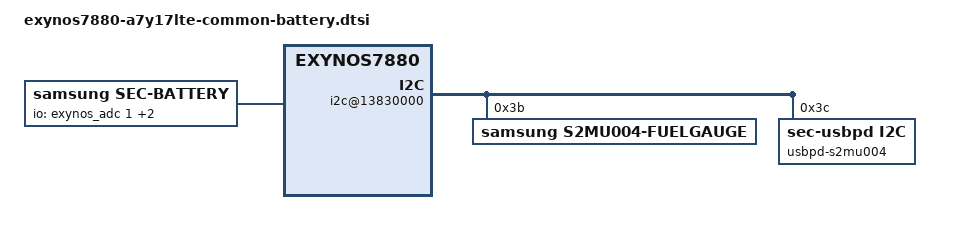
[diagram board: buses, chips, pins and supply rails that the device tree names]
/*
 * SAMSUNG UNIVERSAL7880 board device tree source
 *
 * Copyright (c) 2016 Samsung Electronics Co., Ltd.
 *		http://www.samsung.com
 *
 * This program is free software; you can redistribute it and/or modify
 * it under the terms of the GNU General Public License version 2 as
 * published by the Free Software Foundation.
*/

/ {
	pinctrl@139F0000 {
		fuel_irq: fuel-irq {
			samsung,pins = "gpa0-3";
			samsung,pin-function = <0>;
			samsung,pin-pud = <2>;
			samsung,pin-drv = <0>;
		};

		if_pmic_irq: if-pmic-irq {
			samsung,pins = "gpa2-7";
			samsung,pin-function = <0>;
			samsung,pin-pud = <0>;
			samsung,pin-drv = <0>;
		};

		usbpd_irq: usbpd-irq {
			samsung,pins = "gpa1-3";
			samsung,pin-function = <0xf>;
			samsung,pin-pud = <0>;
			samsung,pin-drv = <0>;
		};
	};

	i2c@13830000 {
		i2c-gpio,delay-us = <5>;
		status = "okay";
		s2mu004-fuelgauge@3B {
			compatible = "samsung,s2mu004-fuelgauge";
			reg = <0x3B>;
			pinctrl-names = "default";
			pinctrl-0 = <&fuel_irq>;
			fuelgauge,fuel_int = <&gpa0 3 0>;
			fuelgauge,fuel_alert_soc = <1>;
			fuelgauge,fuel_alert_vol = <3300>;
			fuelgauge,capacity_max = <1000>;
			fuelgauge,capacity_max_margin = <200>;
			fuelgauge,capacity_min = <0>;
			fuelgauge,capacity_calculation_type = <28>;
			fuelgauge,capacity_full = <3600>;
			fuelgauge,type_str = "SDI";
			fuelgauge,model_type = <1>;
		};
		usbpd-s2mu004@3C {
			compatible = "sec-usbpd,i2c";
			reg = <0x3C>;
			pinctrl-names = "default";
			pinctrl-0     = <&usbpd_irq>;
			usbpd,usbpd_int = <&gpa1 3 0>;
		};
	};

	battery_params {
			battery,battery_data = 
				<
				/***** battery data for 4.35 *****/
				/* battery,battery_table3 */
				229 11 83 11 193 10 48 10 182 9
				67 9 215 8 111 8 244 7 174 7
				84 7 244 6 182 6 136 6 100 6
				70 6 34 6 249 5 199 5 145 5
				57 5 175 1 243 8 132 8 21 8
				166 7 55 7 200 6 89 6 235 5
				124 5 13 5 158 4 47 4 192 3
				81 3 227 2 116 2 5 2 150 1
				39 1 184 0 73 0 219 15

				/* battery,battery_table4 */
				51 51 51 51 51 51 50 51 50 50
				50 51 51 52 53 53 54 56 58 63
				80 154

				/* battery,batcap */
				0x40 0x38 0x10 0x0E /* [0x0E] [0x0F] [0x10] [0x11] */
				/* battery,accum */ 
				0x7 0xD7 /* [0x45] [0x44] */

				/* battery,soc_arr_val */
				11185 10644 10103 9561 9020 8479 7937 7396 6855 6314 5772 5231 4690 4148 3607 3066 2525 1983 1442 901 359 (-182)
				/* battery,ocv_arr_val */
				44709 44058 43407 42757 42157 41576 41022 40501 40016 39595 39118 38638 38351 38136 37965 37820 37654 37444 37170 36926 36174 31965


				/***** battery data for 4.33 *****/
				/* battery,battery_table3 */
				101 11 233 10 110 10 242 9 123 9
				10 9 158 8 56 8 222 7 135 7
				26 7 209 6 158 6 119 6 87 6
				59 6 26 6 239 5 182 5 132 5
				63 5 211 1 222 8 111 8 0 8
				145 7 34 7 179 6 68 6 213 5
				101 5 246 4 135 4 24 4 169 3
				58 3 203 2 92 2 237 1 125 1
				14 1 159 0 48 0 202 15

				/* battery,battery_table4 */
				58 58 58 57 55 55 54 53 53 53
				52 52 53 53 54 54 55 54 58 59
				72 163

				/* battery,batcap */
				0x30 0x34 0x0C 0x0D /* [0x0E] [0x0F] [0x10] [0x11] */
				/* battery,accum */
				0x8 0x00 /* [0x45] [0x44] */

				/* battery,soc_arr_val */
				11084 10542 10000 9458 8915 8373 7830 7288 6745 6202 5660 5117 4575 4032 3490 2947 2405 1862 1320 778 235 (-265)
				/* battery,ocv_arr_val */
				44241 43638 43035 42432 41851 41297 40771 40276 39834 39407 38875 38520 38274 38081 37927 37790 37626 37415 37138 36893 36558 32278
		
				/***** battery data for 4.31 *****/
				/* battery,battery_table3 */
				59 11 189 10 64 10 195 9 78 9
				222 8 119 8 18 8 191 7 98 7
				246 6 186 6 141 6 105 6 77 6
				50 6 9 6 220 5 152 5 127 5
				108 4 168 1 225 8 113 8 0 8
				143 7 30 7 174 6 61 6 204 5
				92 5 235 4 122 4 10 4 153 3
				40 3 183 2 71 2 214 1 102 1
				245 0 132 0 19 0 216 15

				/* battery,battery_table4 */
				54 54 54 54 53 53 54 53 53 53
				53 53 54 54 55 56 57 58 61 65
				87 154

				/* battery,batcap */                                  
				0x68 0x33 0xDA 0x0C /* [0x0E] [0x0F] [0x10] [0x11] */ 
				/* battery,accum */
				0x8 0x00 /* [0x45] [0x44] */

				/* battery,soc_arr_val */
				11100 10550 10000 9450 8899 8349 7799 7248 6698 6148 5597 5047 4497 3947 3396 2846 2296 1746 1195 645 95 (-196)
				/* battery,ocv_arr_val */
				44037 43425 42813 42201 41629 41082 40579 40088 39682 39229 38703 38407 38188 38014 37875 37745 37542 37324 36991 36869 35527 32071

				/***** battery data for 4.29 *****/
				/* battery,battery_table3 */
				141 11 16 11 148 10 24 10 155 9
				40 9 186 8 85 8 245 7 164 7
				55 7 223 6 169 6 128 6 95 6
				68 6 36 6 250 5 199 5 136 5
				119 5 41 3 89 9 230 8 115 8
				0 8 141 7 26 7 167 6 52 6
				192 5 77 5 218 4 103 4 244 3
				129 3 14 3 155 2 40 2 181 1
				66 1 206 0 91 0 232 15

				/* battery,battery_table4 */
				53 53 53 53 53 54 53 54 53 53
				53 53 54 55 55 56 57 60 63 73
				113 128

				/* battery,batcap */                                  
				0x50 0x32 0x94 0x0C /* [0x0E] [0x0F] [0x10] [0x11] */ 
				/* battery,accum */
				0x8 0x00 /* [0x45] [0x44] */

				/* battery,soc_arr_val */
				11686 11124 10562 10000 9438 8876 8314 7752 7190 6628 6066 5505 4943 4381 3819 3257 2695 2133 1570 1008 446 (-116)

				/* battery,ocv_arr_val */
				44437 43830 43223 42616 42009 41444 40907 40414 39948 39550 39020 38588 38327 38124 37963 37830 37678 37470 37221 36912 36829 33952

				/***** battery data for 4.24 *****/
				/* batterybattery_table3 */
				31 11 166 10 45 10 181 9 60 9
				204 8 102 8 3 8 178 7 78 7
				233 6 177 6 133 6 99 6 72 6
				43 6 0 6 209 5 139 5 122 5
				222 3 122 1 100 9 237 8 119 8
				0 8 137 7 19 7 156 6 38 6
				175 5 57 5 194 4 76 4 213 3
				95 3 232 2 114 2 251 1 132 1
				14 1 152 0 33 0 51 15

				/* batterybattery_table4 */
				54 54 54 54 54 54 53 54 54 53
				54 54 54 55 57 58 58 61 65 73
				103 156

				/* batterybatcap */                                  
				0xE8 0x30 0x3A 0x0C /* [0x0E] [0x0F] [0x10] [0x11] */ 
				/* batteryaccum */
				0x8 0x00 /* [0x45] [0x44] */

				/* batterysoc_arr_val */
				11737 11158 10579 10000 9421 8842 8264 7685 7106 6527 5949 5370 4791 4212 3633 3055 2476 1897 1318 740 161 (-1000)

				/* batteryocv_arr_val */
				43902 43312 42722 42132 41542 40997 40497 40017 39619 39129 38638 38365 38152 37984 37851 37708 37500 37271 36931 36845 34832 31846
				>;

			battery,battery_table3 = <229 11 83 11 193 10 48 10 182 9
						67 9 215 8 111 8 244 7 174 7
						84 7 244 6 182 6 136 6 100 6
						70 6 34 6 249 5 199 5 145 5
						57 5 175 1 243 8 132 8 21 8
						166 7 55 7 200 6 89 6 235 5
						124 5 13 5 158 4 47 4 192 3
						81 3 227 2 116 2 5 2 150 1
						39 1 184 0 73 0 219 15>;

			battery,battery_table4 = <51 51 51 51 51 51 50 51 50 50
						50 51 51 52 53 53 54 56 58 63
						80 154>;

			battery,batcap = <0x40 0x38 0x10 0x0E>; /* [0x0E] [0x0F] [0x10] [0x11] */
			battery,accum = <0x7 0xD7>; /* [0x45] [0x44] */

			battery,soc_arr_val = <11185 10644 10103 9561 9020 8479 7937 7396 6855 6314 5772 5231 4690 4148 3607 3066 2525 1983 1442 901 359 (-182)>;
			battery,ocv_arr_val = <44709 44058 43407 42757 42157 41576 41022 40501 40016 39595 39118 38638 38351 38136 37965 37820 37654 37444 37170 36926 36174 31965>;
	};

	pdic-manager {
		/* sink */
		pdic,max_power = <5000>;
		pdic,op_power = <2500>;
		pdic,max_voltage = <6000>;
		pdic,max_current = <2000>;
		pdic,min_current = <500>;

		pdic,giveback = <0>;
		pdic,usb_com_capable = <1>;
		pdic,no_usb_suspend = <1>;

		/* source */
		source,max_voltage = <5000>;
		source,min_voltage = <4000>;
		source,max_power = <2500>;

		/* sink cap */
		sink,capable_max_voltage = <9000>;
	};

	battery {
		status = "okay";
		compatible = "samsung,sec-battery";

		pinctrl-names = "default";

		battery,vendor = "SDI SDI";
		battery,charger_name = "s2mu004-charger";
		battery,fuelgauge_name = "s2mu004-fuelgauge";
		battery,technology = <2>; /* POWER_SUPPLY_TECHNOLOGY_LION */

		battery,chip_vendor = "LSI";
		battery,temp_adc_type = <1>; /* SEC_BATTERY_ADC_TYPE_AP */

		battery,chg_thermal_source = <1>;  /* SEC_CHARGER_THERMAL_SOURCE_ADC */
		battery,chg_temp_check = <1>;
		battery,slave_chg_temp_check = <0>;

		battery,polling_time = <10 30 30 30 3600>;

		battery,temp_table_adc = <311 364 412 489 596 702 779 842 884 939 1038 1098 1130 1204 1277 1307 1390 1497
						1580 1698 1846 1976 2071 2306 2537 2759 2964 3041 3134 3251 3321 3373 3469 3597 3707>;
		battery,temp_table_data = <900 850 800 750 700 650 600 570 550 530 500 480 470 450 430 420 400 370
						350 330 300 270 250 200 150 100 50 30 0 (-30) (-50) (-70) (-100) (-150) (-200)>;

		battery,chg_temp_table_adc = <298 336 396 464 538 662 765 888 943 996 1080 1152 1181 1231 1308 1422 1536
						1617 1708 1833 1957 2048 2270 2490 2690 2881 2957 3042 3138 3210 3262 3339 3455 3555>;
		battery,chg_temp_table_data = <900 850 800 750 700 650 600 570 550 530 500 480 470 450 430 400 370
						350 330 300 270 250 200 150 100 50 30 0 (-30) (-50) (-70) (-100) (-150) (-200)>;

		battery,input_current_limit = <1800 450 450 1800 500 900 1500 450 1000 450 900 900 900 1900 1800 450 450 400 700 1300 300 1000 1500 450 1650 2100 500 1650 80 1800 1650 1400 1000 1000 700 900 900 900 500 1800 1650 3000>;
		battery,fast_charging_current = <2100 450 450 2100 800 1200 1500 450 1200 450 2100 2100 2100 1600 2100 450 450 400 700 1300 300 1000 1500 450 2600 3500 500 2600 80 1800 1000 1400 450 1000 2100 2100 2100 2100 450 2100 2600 3000>;
		battery,full_check_current_1st = <360 0 0 360 360 360 360 360 360 0 360 360 360 360 360 0 0 360 360 360 360 360 360 0 360 360 360 360 0 360 360 360 0 360 360 360 360 360 360 360 360 360>;
		battery,full_check_current_2nd = <180 0 0 180 180 180 180 180 180 0 180 180 180 180 180 0 0 180 180 180 180 180 180 0 180 180 180 180 0 180 180 180 0 180 180 180 180 180 180 180 180 180>;

		battery,wireless_cc_cv = <85>;
		battery,inbat_voltage = <1>;

		battery,inbat_voltage_table_adc = <2823 2803 2775 2748 2719 2695 2668 2638 2609 2582
						2551 2524 2496 2469 2442 2416 2390 2362 2333 2303 2275>;
		battery,inbat_voltage_table_data = <4385 4355 4305 4255 4205 4155 4105 4055 4005 3955
						3905 3855 3805 3755 3705 3655 3605 3555 3505 3455 3405>;

		battery,adc_check_count = <5>;

		battery,cable_check_type = <4>; /* SEC_BATTERY_CABLE_CHECK_PSY */
		battery,cable_source_type = <1>; /* SEC_BATTERY_CABLE_SOURCE_EXTERNAL */
		battery,polling_type = <1>; /* SEC_BATTERY_MONITOR_ALARM */
		battery,monitor_initial_count = <0>;

		battery,pre_afc_input_current = <500>;

		battery,battery_check_type = <0>; /* SEC_BATTERY_CHECK_NONE */
		battery,check_count = <0>;
		battery,check_adc_max = <1440>;
		battery,check_adc_min = <0>;

		battery,ovp_uvlo_check_type = <3>; /* SEC_BATTERY_OVP_UVLO_CHGPOLLING */

		battery,thermal_source = <2>; /* SEC_BATTERY_THERMAL_SOURCE_ADC */

		battery,temp_check_type = <2>; /* SEC_BATTERY_TEMP_CHECK_TEMP */
		battery,temp_check_count = <1>;
		battery,temp_highlimit_threshold_normal = <800>;
		battery,temp_highlimit_recovery_normal = <750>;
		battery,temp_high_threshold_normal = <500>;
		battery,temp_high_recovery_normal = <450>;
		battery,temp_low_threshold_normal = <0>;
		battery,temp_low_recovery_normal = <50>;
		battery,temp_highlimit_threshold_lpm = <800>;
		battery,temp_highlimit_recovery_lpm = <750>;
		battery,temp_high_threshold_lpm = <500>;
		battery,temp_high_recovery_lpm = <450>;
		battery,temp_low_threshold_lpm = <0>;
		battery,temp_low_recovery_lpm = <50>;

		battery,full_check_type = <2>; /* SEC_BATTERY_FULLCHARGED_FG_CURRENT */
		battery,full_check_type_2nd = <2>; /* SEC_BATTERY_FULLCHARGED_FG_CURRENT */
		battery,full_check_count = <1>;
		battery,chg_gpio_full_check = <0>;
		battery,chg_polarity_full_check = <1>;

		battery,chg_heating_prevention_method = <1>; /* SEC_BATTERY_BY_CHANGING_CURRENT */
		battery,chg_12v_high_temp = <615>;
		battery,chg_high_temp = <430>;
		battery,chg_high_temp_recovery = <425>;
		battery,chg_charging_limit_current = <1100>;

		battery,wpc_high_temp = <460 495>;
		battery,wpc_high_temp_recovery = <459 400>;
		battery,wpc_charging_limit_current = <540 400>;
		battery,wpc_heat_temp_recovery = <360>;
		battery,wpc_lcd_on_high_temp = <470>;
		battery,wpc_lcd_on_high_temp_rec = <300>;
		battery,wpc_hv_lcd_on_input_limit_current = <400>;

		battery,sleep_mode_limit_current = <500>;
		battery,wc_full_input_limit_current = <100>;
		battery,wc_heating_input_limit_current = <400>;
		battery,wc_heating_time = <300>; /* 5 min */
		battery,wc_cv_current = <820>;
		battery,wc_cv_pack_current = <630>;

		battery,mix_high_temp = <420>;
		battery,mix_high_chg_temp = <500>;
		battery,mix_high_temp_recovery = <390>;

		/* SEC_BATTERY_FULL_CONDITION_SOC |
		   SEC_BATTERY_FULL_CONDITION_NOTIMEFULL |
		   SEC_BATTERY_FULL_CONDITION_VCELL */
		battery,full_condition_type = <13>;
		battery,full_condition_soc = <93>;
		battery,full_condition_vcell = <4250>;

		battery,recharge_check_count = <1>;
		battery,recharge_condition_type = <4>; /* SEC_BATTERY_RECHARGE_CONDITION_VCELL */
		battery,recharge_condition_soc = <98>;
		battery,recharge_condition_vcell = <4280>;

		battery,expired_time = <11520>; /* 132+60mins */
		battery,recharginig_expired_time = <5400>;
		battery,standard_curr = <2600>;

		battery,charging_total_time = <21600>;
		battery,recharging_total_time = <5400>;
		battery,charging_reset_time = <0>;

		battery,chg_float_voltage = <4350>;

		battery,swelling_high_temp_block = <410>;
		battery,swelling_high_temp_recov = <390>;

		battery,swelling_low_temp_2step_mode = <1>;
		battery,swelling_low_temp_block_1st = <150>;
		battery,swelling_low_temp_recov_1st = <200>;
		battery,swelling_low_temp_block_2nd = <50>;
		battery,swelling_low_temp_recov_2nd = <100>;

		battery,swelling_low_temp_current = <850>;	/* 0.3C */
		battery,swelling_low_temp_topoff = <180>;	/* 0.05C */
		battery,swelling_high_temp_current = <1275>;	/* 0.45C */
		battery,swelling_high_temp_topoff = <180>;	/* 0.05C */

		battery,swelling_drop_float_voltage = <4150>;
		battery,swelling_high_rechg_voltage = <4000>;
		battery,swelling_low_rechg_voltage = <4000>;

		battery,factory_fast_charging_current = <1000>;

		battery,self_discharging_temp_block = <600>;
		battery,self_discharging_volt_block = <4250>;
		battery,self_discharging_temp_recov = <550>;
		battery,self_discharging_temp_pollingtime = <400>;

		battery,siop_event_check_type = <1>;
		battery,siop_call_cv_current = <330>;
		battery,siop_call_cc_current = <330>;

		battery,siop_input_limit_current = <1200>;
		battery,siop_charging_limit_current = <1000>;
		battery,siop_hv_input_limit_current = <700>;
		battery,siop_hv_charging_limit_current = <1200>;
		battery,siop_hv_12v_input_limit_current = <535>;
		battery,siop_hv_12v_charging_limit_current = <1000>;

		battery,siop_wireless_input_limit_current = <600>;
		battery,siop_wireless_charging_limit_current = <1000>;
		battery,siop_hv_wireless_input_limit_current = <600>;
		battery,siop_hv_wireless_charging_limit_current = <1000>;

		battery,ttf_hv_12v_charge_current = <2350>;
		battery,ttf_hv_charge_current = <2200>;
		battery,ttf_hv_wireless_charge_current = <1500>;

		/* cycle, chg_float_voltage, recharge_condition_vcell, full_condition_vcell, full_condition_soc */
		battery,age_data = <0 4350 4280 4250 92	/*4.35*/
				200 4330 4260 4230 91	/*4.33*/
				250 4310 4240 4210 89	/*4.31*/
				300 4290 4220 4190 87	/*4.29*/
				1000 4240 4170 4140 83	/*4.24*/
				>;

		/* values for using CONFIG_STEP_CHARGING */
		battery,step_charging_type = <0x5>;
		battery,step_charging_charge_power = <20000>;
		battery,step_charging_condtion = <4100 4400>;
		battery,step_charging_current = <4200 3000>;
		/* values for not using CONFIG_STEP_CHARGING */
		battery,base_charge_power = <15000>;
		battery,max_charging_current = <2600>;

		battery,max_input_voltage = <9000>; /* mV */
		battery,max_input_current = <3000>;  /* mA */

		battery,prepare_afc_delay = <0>;

		battery,cisd_data_efs_path = "a7y17lte";

		io-channels = <&exynos_adc 1>, <&exynos_adc 3>, <&exynos_adc 6>;
		io-channel-names = "adc-temp", "adc-in-bat", "adc-chg-temp";
		#io-channel-cells = <5>;
		io-channel-ranges;
	};

	s2mu004-charger {
		status = "disable";
		compatible = "samsung,s2mu004-charger";
		battery,is_1MHz_switching = <1>;
		battery,chg_gpio_en = <0>;
		battery,chg_polarity_en = <0>;
		battery,chg_gpio_status = <0>;
		battery,chg_polarity_status = <0>;
	};
};
